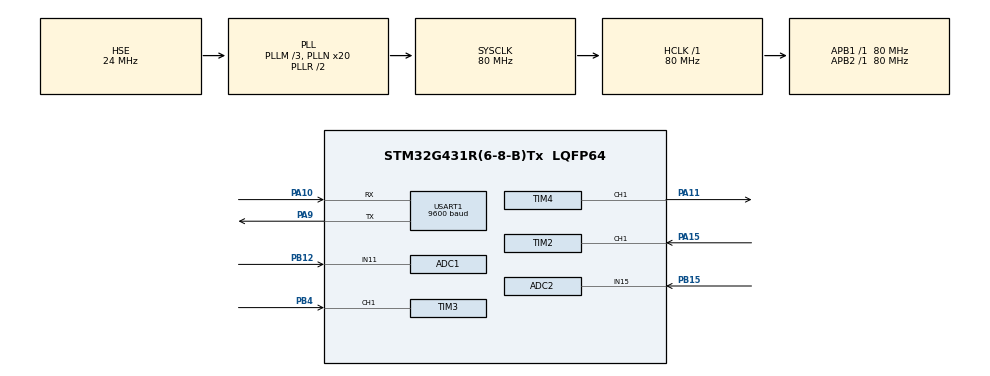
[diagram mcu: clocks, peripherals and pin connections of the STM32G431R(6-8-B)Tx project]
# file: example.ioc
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ADC1.Channel-1\#ChannelRegularConversion=ADC_CHANNEL_11
ADC1.EnableInjectedConversion=DISABLE
ADC1.NbrOfConversion=1
ADC1.NbrOfConversionFlag=1
ADC1.OffsetNumber-1\#ChannelRegularConversion=ADC_OFFSET_NONE
ADC1.Rank-1\#ChannelRegularConversion=1
ADC1.SamplingTime-1\#ChannelRegularConversion=ADC_SAMPLETIME_92CYCLES_5
ADC1.master=1
ADC2.Channel-0\#ChannelRegularConversion=ADC_CHANNEL_15
ADC2.NbrOfConversionFlag=1
ADC2.OffsetNumber-0\#ChannelRegularConversion=ADC_OFFSET_NONE
ADC2.Rank-0\#ChannelRegularConversion=1
ADC2.SamplingTime-0\#ChannelRegularConversion=ADC_SAMPLETIME_92CYCLES_5
FREERTOS.BinarySemaphores01=uartBinarySem,Dynamic,NULL
FREERTOS.Queues01=pwmQueue,16,uint32_t,0,Dynamic,NULL,NULL
FREERTOS.Tasks01=defaultTask,24,512,StartDefaultTask,Default,NULL,Dynamic,NULL,NULL;uart,15,512,UsartTask,As weak,NULL,Dynamic,NULL,NULL;adc,8,256,AdcTask,As weak,NULL,Dynamic,NULL,NULL;led,8,256,LedTask,As weak,NULL,Dynamic,NULL,NULL;freq,16,256,FreqTask,As weak,NULL,Dynamic,NULL,NULL;pwm,15,256,PwmTask,As weak,NULL,Dynamic,NULL,NULL;key,25,256,KeyTask,As weak,NULL,Dynamic,NULL,NULL
FREERTOS.Timers01=key1Timer,Key1Callback,osTimerOnce,As weak,NULL,Dynamic,NULL;key2Timer,key2Callback,osTimerOnce,As weak,NULL,Dynamic,NULL;key3Timer,key3Callback,osTimerOnce,As weak,NULL,Dynamic,NULL;key4Timer,key4Callback,osTimerOnce,As weak,NULL,Dynamic,NULL
FREERTOS.configTOTAL_HEAP_SIZE=11280
Mcu.Family=STM32G4
Mcu.Name=STM32G431R(6-8-B)Tx
Mcu.Package=LQFP64
NVIC.PriorityGroup=NVIC_PRIORITYGROUP_4
NVIC.TIM1_UP_TIM16_IRQn=true\:15\:0\:false\:false\:true\:false\:false\:true\:true
NVIC.TIM7_IRQn=true\:6\:0\:true\:false\:true\:true\:true\:true\:true
NVIC.TimeBase=TIM1_UP_TIM16_IRQn
NVIC.TimeBaseIP=TIM16
NVIC.USART1_IRQn=true\:5\:0\:false\:false\:true\:true\:true\:true\:true
PA10.Mode=Asynchronous
PA10.Signal=USART1_RX
PA11.Signal=S_TIM4_CH1
PA13.Mode=Serial_Wire
PA13.Signal=SYS_JTMS-SWDIO
PA14.Mode=Serial_Wire
PA14.Signal=SYS_JTCK-SWCLK
PA15.GPIO_PuPd=GPIO_NOPULL
PA15.Signal=S_TIM2_CH1
PA9.Mode=Asynchronous
PA9.Signal=USART1_TX
PB12.Mode=IN11-Single-Ended
PB12.Signal=ADC1_IN11
PB15.Mode=IN15-Single-Ended
PB15.Signal=ADC2_IN15
PB4.Signal=S_TIM3_CH1
PF0-OSC_IN.Mode=HSE-External-Oscillator
PF0-OSC_IN.Signal=RCC_OSC_IN
PF1-OSC_OUT.Mode=HSE-External-Oscillator
PF1-OSC_OUT.Signal=RCC_OSC_OUT
ProjectManager.HeapSize=0x200
ProjectManager.StackSize=0x400
ProjectManager.TargetToolchain=MDK-ARM V5.32
RCC.ADC12Freq_Value=80000000
RCC.AHBFreq_Value=80000000
RCC.APB1Freq_Value=80000000
RCC.APB1TimFreq_Value=80000000
RCC.APB2Freq_Value=80000000
RCC.APB2TimFreq_Value=80000000
RCC.CortexFreq_Value=80000000
RCC.EXTERNAL_CLOCK_VALUE=12288000
RCC.HCLKFreq_Value=80000000
RCC.HSE_VALUE=24000000
RCC.HSI48_VALUE=48000000
RCC.HSI_VALUE=16000000
RCC.LSE_VALUE=32768
RCC.PLLM=RCC_PLLM_DIV3
RCC.PLLN=20
RCC.PLLSourceVirtual=RCC_PLLSOURCE_HSE
RCC.SYSCLKFreq_VALUE=80000000
RCC.SYSCLKSource=RCC_SYSCLKSOURCE_PLLCLK
RCC.USBFreq_Value=80000000
RCC.VCOOutputFreq_Value=160000000
SH.S_TIM2_CH1.0=TIM2_CH1,TriggerSource_TI1FP1
SH.S_TIM2_CH1.1=TIM2_CH1,Input_Capture1_from_TI1
SH.S_TIM3_CH1.0=TIM3_CH1,Input_Capture1_from_TI1
SH.S_TIM3_CH1.1=TIM3_CH1,TriggerSource_TI1FP1
SH.S_TIM4_CH1.0=TIM4_CH1,PWM Generation1 CH1
TIM2.AutoReloadPreload=TIM_AUTORELOAD_PRELOAD_ENABLE
TIM2.Channel-Input_Capture1_from_TI1=TIM_CHANNEL_1
TIM2.ICFilter_CH1=15
TIM2.Prescaler=80-1
TIM2.TIM_MasterSlaveMode=TIM_MASTERSLAVEMODE_DISABLE
TIM3.Channel-Input_Capture1_from_TI1=TIM_CHANNEL_1
TIM3.ICFilter_CH1=15
TIM3.ICPolarity_CH1=TIM_INPUTCHANNELPOLARITY_RISING
TIM3.Prescaler=80-1
TIM4.Channel-PWM\ Generation1\ CH1=TIM_CHANNEL_1
TIM4.PeriodNoDither=1000-1
TIM4.Prescaler=80-1
TIM4.PulseNoDither_1=500
TIM7.PeriodNoDither=1000-1
TIM7.Prescaler=8000-1
USART1.BaudRate=9600
USART1.VirtualMode-Asynchronous=VM_ASYNC
VP_FREERTOS_VS_CMSIS_V2.Mode=CMSIS_V2
VP_SYS_VS_DBSignals.Mode=DisableDeadBatterySignals
VP_SYS_VS_tim16.Mode=TIM16
VP_TIM2_VS_ControllerModeReset.Mode=Reset Mode
VP_TIM3_VS_ControllerModeReset.Mode=Reset Mode
VP_TIM7_VS_ClockSourceINT.Mode=Enable_Timer
board=custom

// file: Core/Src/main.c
/* USER CODE BEGIN Header */
/**
  ******************************************************************************
  * @file           : main.c
  * @brief          : Main program body
  ******************************************************************************
  * @attention
  *
  * Copyright (c) 2024 STMicroelectronics.
  * All rights reserved.
  *
  * This software is licensed under terms that can be found in the LICENSE file
  * in the root directory of this software component.
  * If no LICENSE file comes with this software, it is provided AS-IS.
  *
  ******************************************************************************
  */
/* USER CODE END Header */
#include "main.h"
#include "cmsis_os.h"

ADC_HandleTypeDef hadc1;
ADC_HandleTypeDef hadc2;

TIM_HandleTypeDef htim2;
TIM_HandleTypeDef htim3;
TIM_HandleTypeDef htim4;
TIM_HandleTypeDef htim7;

UART_HandleTypeDef huart1;

/* Definitions for defaultTask */
osThreadId_t defaultTaskHandle;
const osThreadAttr_t defaultTask_attributes = {
  .name = "defaultTask",
  .priority = (osPriority_t) osPriorityNormal,
  .stack_size = 512 * 4
};
/* Definitions for uart */
osThreadId_t uartHandle;
const osThreadAttr_t uart_attributes = {
  .name = "uart",
  .priority = (osPriority_t) osPriorityLow7,
  .stack_size = 512 * 4
};
/* Definitions for adc */
osThreadId_t adcHandle;
const osThreadAttr_t adc_attributes = {
  .name = "adc",
  .priority = (osPriority_t) osPriorityLow,
  .stack_size = 256 * 4
};
/* Definitions for led */
osThreadId_t ledHandle;
const osThreadAttr_t led_attributes = {
  .name = "led",
  .priority = (osPriority_t) osPriorityLow,
  .stack_size = 256 * 4
};
/* Definitions for key */
osThreadId_t keyHandle;
const osThreadAttr_t key_attributes = {
  .name = "key",
  .priority = (osPriority_t) osPriorityNormal1,
  .stack_size = 256 * 4
};
/* Definitions for freq */
osThreadId_t freqHandle;
const osThreadAttr_t freq_attributes = {
  .name = "freq",
  .priority = (osPriority_t) osPriorityBelowNormal,
  .stack_size = 256 * 4
};
/* Definitions for pwm */
osThreadId_t pwmHandle;
const osThreadAttr_t pwm_attributes = {
  .name = "pwm",
  .priority = (osPriority_t) osPriorityLow7,
  .stack_size = 256 * 4
};
/* Definitions for pwmQueue */
osMessageQueueId_t pwmQueueHandle;
const osMessageQueueAttr_t pwmQueue_attributes = {
  .name = "pwmQueue"
};
/* Definitions for key1Timer */
osTimerId_t key1TimerHandle;
const osTimerAttr_t key1Timer_attributes = {
  .name = "key1Timer"
};
/* Definitions for key2Timer */
osTimerId_t key2TimerHandle;
const osTimerAttr_t key2Timer_attributes = {
  .name = "key2Timer"
};
/* Definitions for key3Timer */
osTimerId_t key3TimerHandle;
const osTimerAttr_t key3Timer_attributes = {
  .name = "key3Timer"
};
/* Definitions for key4Timer */
osTimerId_t key4TimerHandle;
const osTimerAttr_t key4Timer_attributes = {
  .name = "key4Timer"
};
/* Definitions for uartBinarySem */
osSemaphoreId_t uartBinarySemHandle;
const osSemaphoreAttr_t uartBinarySem_attributes = {
  .name = "uartBinarySem"
};
/* USER CODE BEGIN PV */
extern void Hardware_Init(void);
/* USER CODE END PV */

void SystemClock_Config(void);
static void MX_GPIO_Init(void);
static void MX_TIM7_Init(void);
static void MX_USART1_UART_Init(void);
static void MX_ADC1_Init(void);
static void MX_ADC2_Init(void);
static void MX_TIM2_Init(void);
static void MX_TIM3_Init(void);
static void MX_TIM4_Init(void);
void StartDefaultTask(void *argument);
void UsartTask(void *argument);
void AdcTask(void *argument);
void LedTask(void *argument);
void KeyTask(void *argument);
void Key1Callback(void *argument);
void key2Callback(void *argument);
void key3Callback(void *argument);
void key4Callback(void *argument);
void FreqTask(void *argument);
void PwmTask(void *argument);

int main(void)
{

  /* MCU Configuration--------------------------------------------------------*/

  /* Reset of all peripherals, Initializes the Flash interface and the Systick. */
  HAL_Init();

  /* Configure the system clock */
  SystemClock_Config();

  /* Initialize all configured peripherals */
  MX_GPIO_Init();
  MX_TIM7_Init();
  MX_USART1_UART_Init();
  MX_ADC1_Init();
  MX_ADC2_Init();
  MX_TIM2_Init();
  MX_TIM3_Init();
  MX_TIM4_Init();
  /* USER CODE BEGIN 2 */
	Hardware_Init();
  /* USER CODE END 2 */

  /* Init scheduler */
  osKernelInitialize();

  /* Create the semaphores(s) */
  /* creation of uartBinarySem */
  uartBinarySemHandle = osSemaphoreNew(1, 0, &uartBinarySem_attributes);

  /* Create the timer(s) */
  /* creation of key1Timer */
  key1TimerHandle = osTimerNew(Key1Callback, osTimerOnce, NULL, &key1Timer_attributes);

  /* creation of key2Timer */
  key2TimerHandle = osTimerNew(key2Callback, osTimerOnce, NULL, &key2Timer_attributes);

  /* creation of key3Timer */
  key3TimerHandle = osTimerNew(key3Callback, osTimerOnce, NULL, &key3Timer_attributes);

  /* creation of key4Timer */
  key4TimerHandle = osTimerNew(key4Callback, osTimerOnce, NULL, &key4Timer_attributes);

  /* Create the queue(s) */
  /* creation of pwmQueue */
  pwmQueueHandle = osMessageQueueNew (16, sizeof(uint32_t), &pwmQueue_attributes);

  /* Create the thread(s) */
  /* creation of defaultTask */
  defaultTaskHandle = osThreadNew(StartDefaultTask, NULL, &defaultTask_attributes);

  /* creation of uart */
  uartHandle = osThreadNew(UsartTask, NULL, &uart_attributes);

  /* creation of adc */
  adcHandle = osThreadNew(AdcTask, NULL, &adc_attributes);

  /* creation of led */
  ledHandle = osThreadNew(LedTask, NULL, &led_attributes);

  /* creation of key */
  keyHandle = osThreadNew(KeyTask, NULL, &key_attributes);

  /* creation of freq */
  freqHandle = osThreadNew(FreqTask, NULL, &freq_attributes);

  /* creation of pwm */
  pwmHandle = osThreadNew(PwmTask, NULL, &pwm_attributes);

  /* Start scheduler */
  osKernelStart();

  /* We should never get here as control is now taken by the scheduler */

  /* Infinite loop */
  while (1)
  {

  }
}

void SystemClock_Config(void)
{
  RCC_OscInitTypeDef RCC_OscInitStruct = {0};
  RCC_ClkInitTypeDef RCC_ClkInitStruct = {0};

  /** Configure the main internal regulator output voltage
  */
  HAL_PWREx_ControlVoltageScaling(PWR_REGULATOR_VOLTAGE_SCALE1);

  /** Initializes the RCC Oscillators according to the specified parameters
  * in the RCC_OscInitTypeDef structure.
  */
  RCC_OscInitStruct.OscillatorType = RCC_OSCILLATORTYPE_HSE;
  RCC_OscInitStruct.HSEState = RCC_HSE_ON;
  RCC_OscInitStruct.PLL.PLLState = RCC_PLL_ON;
  RCC_OscInitStruct.PLL.PLLSource = RCC_PLLSOURCE_HSE;
  RCC_OscInitStruct.PLL.PLLM = RCC_PLLM_DIV3;
  RCC_OscInitStruct.PLL.PLLN = 20;
  RCC_OscInitStruct.PLL.PLLP = RCC_PLLP_DIV2;
  RCC_OscInitStruct.PLL.PLLQ = RCC_PLLQ_DIV2;
  RCC_OscInitStruct.PLL.PLLR = RCC_PLLR_DIV2;
  if (HAL_RCC_OscConfig(&RCC_OscInitStruct) != HAL_OK)
  {
    Error_Handler();
  }

  /** Initializes the CPU, AHB and APB buses clocks
  */
  RCC_ClkInitStruct.ClockType = RCC_CLOCKTYPE_HCLK|RCC_CLOCKTYPE_SYSCLK
                              |RCC_CLOCKTYPE_PCLK1|RCC_CLOCKTYPE_PCLK2;
  RCC_ClkInitStruct.SYSCLKSource = RCC_SYSCLKSOURCE_PLLCLK;
  RCC_ClkInitStruct.AHBCLKDivider = RCC_SYSCLK_DIV1;
  RCC_ClkInitStruct.APB1CLKDivider = RCC_HCLK_DIV1;
  RCC_ClkInitStruct.APB2CLKDivider = RCC_HCLK_DIV1;

  if (HAL_RCC_ClockConfig(&RCC_ClkInitStruct, FLASH_LATENCY_2) != HAL_OK)
  {
    Error_Handler();
  }
}

static void MX_ADC1_Init(void)
{

  ADC_MultiModeTypeDef multimode = {0};
  ADC_ChannelConfTypeDef sConfig = {0};

  /** Common config
  */
  hadc1.Instance = ADC1;
  hadc1.Init.ClockPrescaler = ADC_CLOCK_SYNC_PCLK_DIV2;
  hadc1.Init.Resolution = ADC_RESOLUTION_12B;
  hadc1.Init.DataAlign = ADC_DATAALIGN_RIGHT;
  hadc1.Init.GainCompensation = 0;
  hadc1.Init.ScanConvMode = ADC_SCAN_DISABLE;
  hadc1.Init.EOCSelection = ADC_EOC_SINGLE_CONV;
  hadc1.Init.LowPowerAutoWait = DISABLE;
  hadc1.Init.ContinuousConvMode = DISABLE;
  hadc1.Init.NbrOfConversion = 1;
  hadc1.Init.DiscontinuousConvMode = DISABLE;
  hadc1.Init.ExternalTrigConv = ADC_SOFTWARE_START;
  hadc1.Init.ExternalTrigConvEdge = ADC_EXTERNALTRIGCONVEDGE_NONE;
  hadc1.Init.DMAContinuousRequests = DISABLE;
  hadc1.Init.Overrun = ADC_OVR_DATA_PRESERVED;
  hadc1.Init.OversamplingMode = DISABLE;
  if (HAL_ADC_Init(&hadc1) != HAL_OK)
  {
    Error_Handler();
  }

  /** Configure the ADC multi-mode
  */
  multimode.Mode = ADC_MODE_INDEPENDENT;
  if (HAL_ADCEx_MultiModeConfigChannel(&hadc1, &multimode) != HAL_OK)
  {
    Error_Handler();
  }

  /** Configure Regular Channel
  */
  sConfig.Channel = ADC_CHANNEL_11;
  sConfig.Rank = ADC_REGULAR_RANK_1;
  sConfig.SamplingTime = ADC_SAMPLETIME_92CYCLES_5;
  sConfig.SingleDiff = ADC_SINGLE_ENDED;
  sConfig.OffsetNumber = ADC_OFFSET_NONE;
  sConfig.Offset = 0;
  if (HAL_ADC_ConfigChannel(&hadc1, &sConfig) != HAL_OK)
  {
    Error_Handler();
  }

}

static void MX_ADC2_Init(void)
{

  ADC_ChannelConfTypeDef sConfig = {0};

  /** Common config
  */
  hadc2.Instance = ADC2;
  hadc2.Init.ClockPrescaler = ADC_CLOCK_SYNC_PCLK_DIV2;
  hadc2.Init.Resolution = ADC_RESOLUTION_12B;
  hadc2.Init.DataAlign = ADC_DATAALIGN_RIGHT;
  hadc2.Init.GainCompensation = 0;
  hadc2.Init.ScanConvMode = ADC_SCAN_DISABLE;
  hadc2.Init.EOCSelection = ADC_EOC_SINGLE_CONV;
  hadc2.Init.LowPowerAutoWait = DISABLE;
  hadc2.Init.ContinuousConvMode = DISABLE;
  hadc2.Init.NbrOfConversion = 1;
  hadc2.Init.DiscontinuousConvMode = DISABLE;
  hadc2.Init.ExternalTrigConv = ADC_SOFTWARE_START;
  hadc2.Init.ExternalTrigConvEdge = ADC_EXTERNALTRIGCONVEDGE_NONE;
  hadc2.Init.DMAContinuousRequests = DISABLE;
  hadc2.Init.Overrun = ADC_OVR_DATA_PRESERVED;
  hadc2.Init.OversamplingMode = DISABLE;
  if (HAL_ADC_Init(&hadc2) != HAL_OK)
  {
    Error_Handler();
  }

  /** Configure Regular Channel
  */
  sConfig.Channel = ADC_CHANNEL_15;
  sConfig.Rank = ADC_REGULAR_RANK_1;
  sConfig.SamplingTime = ADC_SAMPLETIME_92CYCLES_5;
  sConfig.SingleDiff = ADC_SINGLE_ENDED;
  sConfig.OffsetNumber = ADC_OFFSET_NONE;
  sConfig.Offset = 0;
  if (HAL_ADC_ConfigChannel(&hadc2, &sConfig) != HAL_OK)
  {
    Error_Handler();
  }

}

static void MX_TIM2_Init(void)
{

  TIM_SlaveConfigTypeDef sSlaveConfig = {0};
  TIM_MasterConfigTypeDef sMasterConfig = {0};
  TIM_IC_InitTypeDef sConfigIC = {0};

  htim2.Instance = TIM2;
  htim2.Init.Prescaler = 80-1;
  htim2.Init.CounterMode = TIM_COUNTERMODE_UP;
  htim2.Init.Period = 4294967295;
  htim2.Init.ClockDivision = TIM_CLOCKDIVISION_DIV1;
  htim2.Init.AutoReloadPreload = TIM_AUTORELOAD_PRELOAD_ENABLE;
  if (HAL_TIM_Base_Init(&htim2) != HAL_OK)
  {
    Error_Handler();
  }
  if (HAL_TIM_IC_Init(&htim2) != HAL_OK)
  {
    Error_Handler();
  }
  sSlaveConfig.SlaveMode = TIM_SLAVEMODE_RESET;
  sSlaveConfig.InputTrigger = TIM_TS_TI1FP1;
  sSlaveConfig.TriggerPolarity = TIM_INPUTCHANNELPOLARITY_RISING;
  sSlaveConfig.TriggerFilter = 0;
  if (HAL_TIM_SlaveConfigSynchro(&htim2, &sSlaveConfig) != HAL_OK)
  {
    Error_Handler();
  }
  sMasterConfig.MasterOutputTrigger = TIM_TRGO_RESET;
  sMasterConfig.MasterSlaveMode = TIM_MASTERSLAVEMODE_DISABLE;
  if (HAL_TIMEx_MasterConfigSynchronization(&htim2, &sMasterConfig) != HAL_OK)
  {
    Error_Handler();
  }
  sConfigIC.ICPolarity = TIM_INPUTCHANNELPOLARITY_RISING;
  sConfigIC.ICSelection = TIM_ICSELECTION_DIRECTTI;
  sConfigIC.ICPrescaler = TIM_ICPSC_DIV1;
  sConfigIC.ICFilter = 15;
  if (HAL_TIM_IC_ConfigChannel(&htim2, &sConfigIC, TIM_CHANNEL_1) != HAL_OK)
  {
    Error_Handler();
  }

}

static void MX_TIM3_Init(void)
{

  TIM_SlaveConfigTypeDef sSlaveConfig = {0};
  TIM_MasterConfigTypeDef sMasterConfig = {0};
  TIM_IC_InitTypeDef sConfigIC = {0};

  htim3.Instance = TIM3;
  htim3.Init.Prescaler = 80-1;
  htim3.Init.CounterMode = TIM_COUNTERMODE_UP;
  htim3.Init.Period = 65535;
  htim3.Init.ClockDivision = TIM_CLOCKDIVISION_DIV1;
  htim3.Init.AutoReloadPreload = TIM_AUTORELOAD_PRELOAD_DISABLE;
  if (HAL_TIM_Base_Init(&htim3) != HAL_OK)
  {
    Error_Handler();
  }
  if (HAL_TIM_IC_Init(&htim3) != HAL_OK)
  {
    Error_Handler();
  }
  sSlaveConfig.SlaveMode = TIM_SLAVEMODE_RESET;
  sSlaveConfig.InputTrigger = TIM_TS_TI1FP1;
  sSlaveConfig.TriggerPolarity = TIM_INPUTCHANNELPOLARITY_RISING;
  sSlaveConfig.TriggerFilter = 0;
  if (HAL_TIM_SlaveConfigSynchro(&htim3, &sSlaveConfig) != HAL_OK)
  {
    Error_Handler();
  }
  sMasterConfig.MasterOutputTrigger = TIM_TRGO_RESET;
  sMasterConfig.MasterSlaveMode = TIM_MASTERSLAVEMODE_DISABLE;
  if (HAL_TIMEx_MasterConfigSynchronization(&htim3, &sMasterConfig) != HAL_OK)
  {
    Error_Handler();
  }
  sConfigIC.ICPolarity = TIM_INPUTCHANNELPOLARITY_RISING;
  sConfigIC.ICSelection = TIM_ICSELECTION_DIRECTTI;
  sConfigIC.ICPrescaler = TIM_ICPSC_DIV1;
  sConfigIC.ICFilter = 15;
  if (HAL_TIM_IC_ConfigChannel(&htim3, &sConfigIC, TIM_CHANNEL_1) != HAL_OK)
  {
    Error_Handler();
  }

}

static void MX_TIM4_Init(void)
{

  TIM_MasterConfigTypeDef sMasterConfig = {0};
  TIM_OC_InitTypeDef sConfigOC = {0};

  htim4.Instance = TIM4;
  htim4.Init.Prescaler = 80-1;
  htim4.Init.CounterMode = TIM_COUNTERMODE_UP;
  htim4.Init.Period = 999;
  htim4.Init.ClockDivision = TIM_CLOCKDIVISION_DIV1;
  htim4.Init.AutoReloadPreload = TIM_AUTORELOAD_PRELOAD_DISABLE;
  if (HAL_TIM_PWM_Init(&htim4) != HAL_OK)
  {
    Error_Handler();
  }
  sMasterConfig.MasterOutputTrigger = TIM_TRGO_RESET;
  sMasterConfig.MasterSlaveMode = TIM_MASTERSLAVEMODE_DISABLE;
  if (HAL_TIMEx_MasterConfigSynchronization(&htim4, &sMasterConfig) != HAL_OK)
  {
    Error_Handler();
  }
  sConfigOC.OCMode = TIM_OCMODE_PWM1;
  sConfigOC.Pulse = 500;
  sConfigOC.OCPolarity = TIM_OCPOLARITY_HIGH;
  sConfigOC.OCFastMode = TIM_OCFAST_DISABLE;
  if (HAL_TIM_PWM_ConfigChannel(&htim4, &sConfigOC, TIM_CHANNEL_1) != HAL_OK)
  {
    Error_Handler();
  }
  HAL_TIM_MspPostInit(&htim4);

}

static void MX_TIM7_Init(void)
{

  TIM_MasterConfigTypeDef sMasterConfig = {0};

  htim7.Instance = TIM7;
  htim7.Init.Prescaler = 8000-1;
  htim7.Init.CounterMode = TIM_COUNTERMODE_UP;
  htim7.Init.Period = 999;
  htim7.Init.AutoReloadPreload = TIM_AUTORELOAD_PRELOAD_DISABLE;
  if (HAL_TIM_Base_Init(&htim7) != HAL_OK)
  {
    Error_Handler();
  }
  sMasterConfig.MasterOutputTrigger = TIM_TRGO_RESET;
  sMasterConfig.MasterSlaveMode = TIM_MASTERSLAVEMODE_DISABLE;
  if (HAL_TIMEx_MasterConfigSynchronization(&htim7, &sMasterConfig) != HAL_OK)
  {
    Error_Handler();
  }

}

static void MX_USART1_UART_Init(void)
{

  huart1.Instance = USART1;
  huart1.Init.BaudRate = 9600;
  huart1.Init.WordLength = UART_WORDLENGTH_8B;
  huart1.Init.StopBits = UART_STOPBITS_1;
  huart1.Init.Parity = UART_PARITY_NONE;
  huart1.Init.Mode = UART_MODE_TX_RX;
  huart1.Init.HwFlowCtl = UART_HWCONTROL_NONE;
  huart1.Init.OverSampling = UART_OVERSAMPLING_16;
  huart1.Init.OneBitSampling = UART_ONE_BIT_SAMPLE_DISABLE;
  huart1.Init.ClockPrescaler = UART_PRESCALER_DIV1;
  huart1.AdvancedInit.AdvFeatureInit = UART_ADVFEATURE_NO_INIT;
  if (HAL_UART_Init(&huart1) != HAL_OK)
  {
    Error_Handler();
  }
  if (HAL_UARTEx_SetTxFifoThreshold(&huart1, UART_TXFIFO_THRESHOLD_1_8) != HAL_OK)
  {
    Error_Handler();
  }
  if (HAL_UARTEx_SetRxFifoThreshold(&huart1, UART_RXFIFO_THRESHOLD_1_8) != HAL_OK)
  {
    Error_Handler();
  }
  if (HAL_UARTEx_DisableFifoMode(&huart1) != HAL_OK)
  {
    Error_Handler();
  }

}

static void MX_GPIO_Init(void)
{

  /* GPIO Ports Clock Enable */
  __HAL_RCC_GPIOF_CLK_ENABLE();
  __HAL_RCC_GPIOB_CLK_ENABLE();
  __HAL_RCC_GPIOA_CLK_ENABLE();

}

/* USER CODE BEGIN Header_StartDefaultTask */
/**
  * @brief  Function implementing the defaultTask thread.
  * @param  argument: Not used
  * @retval None
  */
extern int app(void);

extern void UartCallback(void);
/* USER CODE END Header_StartDefaultTask */
void StartDefaultTask(void *argument)
{
  /* USER CODE BEGIN 5 */
  /* Infinite loop */
    if (app() != 0) {
        Error_Handler();
    }
    osThreadExit();
  /* USER CODE END 5 */
}

__weak void UsartTask(void *argument)
{
  for(;;)
  {
    osDelay(1);
  }
}

__weak void AdcTask(void *argument)
{
  for(;;)
  {
    osDelay(1);
  }
}

__weak void LedTask(void *argument)
{
  for(;;)
  {
    osDelay(1);
  }
}

__weak void KeyTask(void *argument)
{
  for(;;)
  {
    osDelay(1);
  }
}

/* Key1Callback function */
__weak void Key1Callback(void *argument)
{
}

/* key2Callback function */
__weak void key2Callback(void *argument)
{
}

/* key3Callback function */
__weak void key3Callback(void *argument)
{
}

/* key4Callback function */
__weak void key4Callback(void *argument)
{
}

__weak void FreqTask(void *argument)
{
  for(;;)
  {
    osDelay(1);
  }
}

__weak void PwmTask(void *argument)
{
  for(;;)
  {
    osDelay(1);
  }
}

void HAL_TIM_PeriodElapsedCallback(TIM_HandleTypeDef *htim)
{
  if (htim->Instance == TIM16) {
    HAL_IncTick();
  }
  /* USER CODE BEGIN Callback 1 */
    if (htim->Instance == TIM7) {
        UartCallback();
    }
  /* USER CODE END Callback 1 */
}

void Error_Handler(void)
{
  __disable_irq();
  while (1)
  {
  }
}
